# cyt4bf register map
Vendor: Cypress Semiconductor; Series: cyt4bf; File version: 1.0
CPU: CM7 r0p1, little endian, MPU, FPU, VTOR, 3 interrupt priority bits
Registers are 32-bit, read-write, reset 0x0 unless marked. A register's access mark holds for its fields unless they carry their own. Offsets are from the block's base; [hi:lo] are bit positions; 'fields as' and 'values as' point back to an identical list; <NAME> marks a mode.

## FLEXRAY0 (part 1 of 3) — FlexRay Bus Interface
Base 0x40560000
0x00 CTL — Control Register
  [31] ENABLED — This bit enables the operation of this IP. '0' : Disable. Registers FLEXRAY.CTL and FLEXRAY.DMA_CTL can be accessed normally. Access to all other registers within FLEXRAY results in a bus error response. '1' : Enable
    0=DISABLE (N/A); 1=ENABLE (N/A)
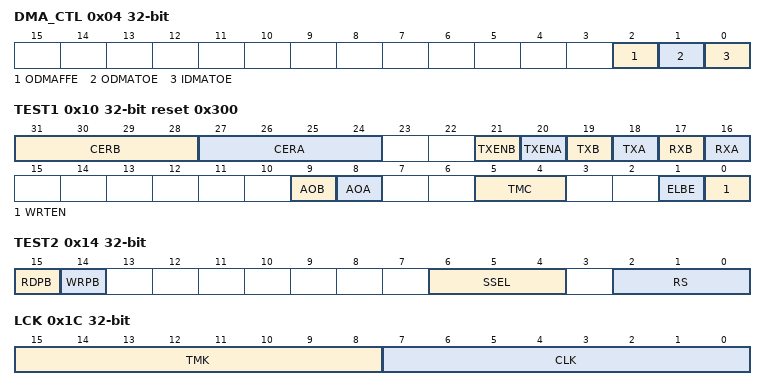
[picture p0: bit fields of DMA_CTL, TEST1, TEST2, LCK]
0x04 DMA_CTL — DMA Control Register
  [all] fields
    0=DISABLE (N/A); 1=ENABLE (N/A)
  [2] ODMAFFE — OBF DMA FIFO enable '0' : Disable: tr_obf_out is postponed until OBF is not busy. '1' : Enable: tr_obf_out is postponed until OBF is not busy AND the receive FIFO is not empty.
  [1] ODMATOE — OBF DMA trigger output enable '0' : Disable: tr_obf_out = '0'. '1' : Enable: tr_obf_out is asserted after detection of tr_obf_in according to the setting of ODMAFFE.
  [0] IDMATOE — IBF DMA trigger output enable '0' : Disable: tr_ibf_out = '0'. '1' : Enable: tr_ibf_out is asserted after the detection of tr_ibf_in, postponed until IBF is not busy.
0x10 TEST1 reset 0x300 — Test Register 1
  [31:28] CERB ro
    0=NO_CODING_ERR (N/A); 1=HEADER_CRC_ERR (N/A); 2=FRAME_CRC_ERR (N/A); 3=FRAME_START_SEQ_FSS_LONG (N/A); 4=FIRST_BIT_OF_BSS_LOW (N/A); 5=SECOND_BIT_OF_BSS_HIGH (N/A); 6=FIRST_BIT_OF_FES_HIGH (N/A); 7=SECOND_BIT_OF_FES_LOW (N/A); 8=CAS_MTS_SYMBOL_SHORT (N/A); 9=CAS_MTS_SYMBOL_LONG (N/A)
  [27:24] CERA ro
    values as CERB
  [21] TXENB — Control of Channel B Transmit Enable Pin This is used to test the interface to the physical layer (connectivity test) by driving the pin. 0 = eray_txen2_n pin drives a '0' 1 = eray_txen2_n pin drives a '1'
    0=ERAY_TXEN2_N_0 (N/A); 1=ERAY_TXEN2_N_1 (N/A)
  [20] TXENA — Control of Channel A Transmit Enable Pin This is used to test the interface to the physical layer (connectivity test) by driving the pin. 0 = eray_txen1_n pin drives a '0' 1 = eray_txen1_n pin drives a '1'
    0=ERAY_TXEN1_N_0 (N/A); 1=ERAY_TXEN1_N_1 (N/A)
  [19] TXB — Control of Channel B Transmit Pin This is used to test the interface to the physical layer (connectivity test) by driving the pin. 0 = eray_txd2 pin drives a '0' 1 = eray_txd2 pin drives a '1'
    0=ERAY_TXD2_0 (N/A); 1=ERAY_TXD2_1 (N/A)
  [18] TXA — Control of Channel A Transmit Pin This is used to test the interface to the physical layer (connectivity test) by driving the pin. 0 = eray_txd1 pin drives a '0' 1 = eray_txd1 pin drives a '1'
    0=ERAY_TXD1_0 (N/A); 1=ERAY_TXD1_1 (N/A)
  [17] RXB ro — Monitor Channel B Receive Pin This is used to test the interface to the physical layer (connectivity test) by reading the pin. 0 = eray_rxd2 = '0' 1 = eray_rxd2 = '1'
    0=ERAY_RXD2_0 (N/A); 1=ERAY_RXD2_1 (N/A)
  [16] RXA ro — Monitor Channel A Receive Pin This is used to test the interface to the physical layer (connectivity test) by reading the pin. 0 = eray_rxd1 = '0' 1 = eray_rxd1 = '1'
    0=ERAY_RXD1_0 (N/A); 1=ERAY_RXD1_1 (N/A)
  [9] AOB ro — Activity on B AOB is set when there is activity on channel B. It is reset when 11 consecutive '1' bits are detected or if the POC state is DEFAULT_CONFIG or CONFIG. During STARTUP, NORMAL_ACTIVE, or NORMAL_PASSIVE the function of AOB is the inverse of zChannel- Idle as specified in the FlexRay protocol spec v2.1, chapter 3, BITSTRB process. AOB should be ignored in all other POC states. 1 = Activity detected, channel B not idle 0 = No activity detected, channel B idle
    0=NOACT_DETECT_CH_B_IDLE (N/A); 1=ACT_DETECT_CH_B_NOT_IDLE (N/A)
  [8] AOA ro — Activity on A AOA is set when there is activity on channel A. It is reset when 11 consecutive '1' bits are detected or if the POC state is DEFAULT_CONFIG or CONFIG. During STARTUP, NORMAL_ACTIVE, or NORMAL_PASSIVE the function of AOA is the inverse of zChannelIdle as specified in the FlexRay protocol spec v2.1, chapter 3, BITSTRB process. AOA should be ignored in all other POC states. 1 = Activity detected, channel A not idle 0 = No activity detected, channel A idle
    0=NOACT_DETECT_CH_A_IDLE (N/A); 1=ACT_DETECT_CH_A_NOT_IDLE (N/A)
  [5:4] TMC — Test Multiplexer Control 00, 11= Normal signal path (default) 01 = RAM Test Mode - Internal busses are multiplexed to make all RAM blocks of the ERay module directly accessible by the Host. This mode is intended to enable testing of the embedded RAM blocks during production testing. 10 = I/O Test Mode - Output pins eray_txd1, eray_txd2, eray_txen1_n, eray_txen2_n, are driven to the values defined by bits TXA, TXB, TXENA, TXENB. The values applied to the input pins eray_rxd1, eray_rxd2 can be read from register bits RXA, RXB.
    0=NORMAL_SIGNAL_PATH (N/A); 3=NORMAL_SIGNAL_PATH_MIRROR (N/A); 1=RAM_TEST_MODE (N/A); 2=IO_TEST_MODE (N/A)
  [1] ELBE — External Loop Back Enable There are two possibilities to perform a Loop Back test. External Loop Back via physical layer or internal Loop Back for in-system self-test (default). In case of an internal Loop Back pins eray_txen1,2_n are in their inactive state, pins eray_txd1,2 are set to HIGH, pins eray_rxd1,2 are not evaluated. Bit ELBE is evaluated only when POC is in Loop Back Mode and test multiplexer control is in non-multiplexing mode TMC[1:0] = '00'. 1 = External Loop Back 0 = Internal Loop Back (default)
    0=INTERNAL_LOOP_BACK (N/A); 1=EXTERNAL_LOOP_BACK (N/A)
  [0] WRTEN — Write Test Register Enable Enables write access to the test registers. To set the bit from '0' to '1' the test mode key has to be written as defined in [01]Section 4.3.3 Lock Register (LCK). The unlock sequence is not required when WRTEN is kept at '1' while other bits of the register are changed. The bit can be reset to '0' at any time. 1 = Write access to test registers enabled 0 = Write access to test registers disabled
    0=TEST_REG_WR_DISABLED (N/A); 1=TEST_REG_WR_ENABLED (N/A)
0x14 TEST2 — Test Register 2
  [15] RDPB ro — Read Parity Bit Value of parity bit read from bit 32 of the addressed RAM word.
  [14] WRPB — Write Parity Bit Value of parity bit to be written to bit 32 of the addressed RAM word.
  [6:4] SSEL — Segment Select To enable access to the complete Message RAM (8192 byte addresses) the Message RAM is segmented. 000 = access to RAM bytes 0000h to 03FFh enabled 001 = access to RAM bytes 0400h to 07FFh enabled 010 = access to RAM bytes 0800h to 0BFFh enabled 011 = access to RAM bytes 0C00h to 0FFFh enabled 100 = access to RAM bytes 1000h to 13FFh enabled 101 = access to RAM bytes 1400h to 17FFh enabled 110 = access to RAM bytes 1800h to 1BFFh enabled 111 = access to RAM bytes 1C00h to 1FFFh enabled
    0=ADDR_0000_TO_03FF_ENABLED (N/A); 1=ADDR_0400_TO_07FF_ENABLED (N/A); 2=ADDR_0800_TO_0BFF_ENABLED (N/A); 3=ADDR_0C00_TO_0FFF_ENABLED (N/A); 4=ADDR_1000_TO_13FF_ENABLED (N/A); 5=ADDR_1400_TO_17FF_ENABLED (N/A); 6=ADDR_1800_TO_1BFF_ENABLED (N/A); 7=ADDR_1C00_TO_1FFF_ENABLED (N/A)
  [2:0] RS — RAM Select In RAM Test mode the RAM blocks selected by RS[2:0] are mapped to module address 0x400 to 7FF (1024 byte addresses). 000 = Input Buffer RAM 1 (IBF1) 001 = Input Buffer RAM 2 (IBF2) 010 = Output Buffer RAM 1 (OBF1) 011 = Output Buffer RAM 2 (OBF2) 100 = Transient Buffer RAM A (TBF1) 101 = Transient Buffer RAM B (TBF2) 110 = Message RAM (MBF) 111 = unused
    0=IBF1 (N/A); 1=IBF2 (N/A); 2=OBF1 (N/A); 3=OBF2 (N/A); 4=TBF1 (N/A); 5=TBF2 (N/A); 6=MBF (N/A)
0x1C LCK wo — Lock Register
  [15:8] TMK — Test Mode Key To write bit TEST1.WRTEN, the write operation has to be directly preceded by two consecutive write accesses to the Test Mode Key (unlock sequence). If the write sequence below is interrupted by other write accesses between the second write to the Test Mode Key and the write access to the TEST1 register, TEST1.WRTEN is not set to '1' and the sequence has to be repeated. First write: LCK.TMK[7:0] = '0111 0101' (0x75) Second write: LCK.TMK[7:0] = '1000 1010' (0x8A) Third write: TEST1.WRTEN = '1'
  [7:0] CLK — Configuration Lock Key To leave CONFIG state by writing SUCC1.CMD[3:0] (commands READY, MONITOR_MODE, ATM, LOOP_BACK), the write operation has to be directly preceded by two write accesses to the Configuration Lock Key (unlock sequence). If the write sequence below is interrupted by other write accesses between the second write to the Configuration Lock Key and the write access to the SUCC1 register, the CC remains in CONFIG state and the sequence has to be repeated. First write: LCK.CLK[7:0] = '1100 1110' (0xCE) Second write: LCK.CLK[7:0] = '0011 0001' (0x31) Third write: SUCC1.CMD[3:0]
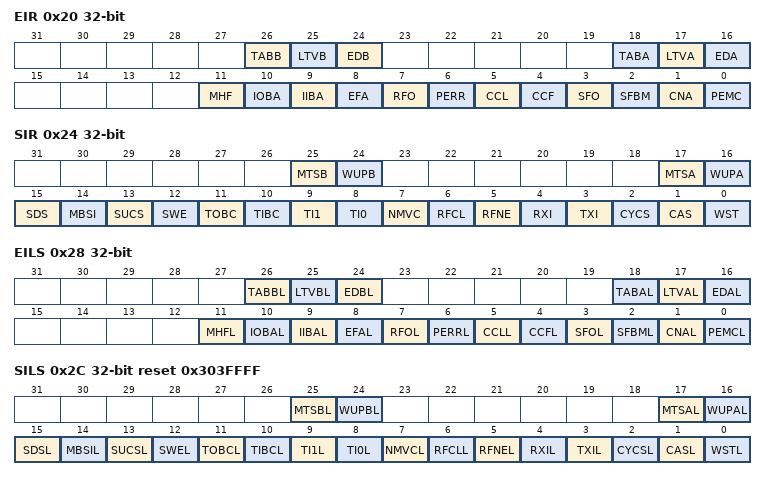
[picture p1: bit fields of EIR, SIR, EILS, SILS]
0x20 EIR — Error Interrupt Register
  [26] TABB — Transmission Across Boundary Channel B The flag signals to the Host that a transmission across a slot boundary occurred for channel B. 1 = Transmission across slot boundary detected on channel B 0 = No transmission across slot boundary detected on channel B
    0=NO_CH_B_TX_ACROSS_SLOT_BOUND_DETECTED (N/A); 1=CH_B_TX_ACROSS_SLOT_BOUND_DETECTED (N/A)
  [25] LTVB — Latest Transmit Violation Channel B The flag signals a latest transmit violation on channel B to the Host. 1 = Latest transmit violation detected on channel B 0 = No latest transmit violation detected on channel B
    0=NO_CH_B_LATEST_TX_VIOLATION_DETECTED (N/A); 1=CH_B_LATEST_TX_VIOLATION_DETECTED (N/A)
  [24] EDB — Error Detected on Channel B This bit is set whenever one of the flags ACS.SEDB, ACS.CEDB, ACS.CIB, ACS.SBVB changes from '0' to '1'. 1 = Error detected on channel B 0 = No error detected on channel B
    0=NO_CH_B_ERR_DETECTED (N/A); 1=CH_B_ERR_DETECTED (N/A)
  [18] TABA — Transmission Across Boundary Channel A The flag signals to the Host that a transmission across a slot boundary occurred for channel A. 1 = Transmission across slot boundary detected on channel A 0 = No transmission across slot boundary detected on channel A
    0=NO_CH_A_TX_ACROSS_SLOT_BOUND_DETECTED (N/A); 1=CH_A_TX_ACROSS_SLOT_BOUND_DETECTED (N/A)
  [17] LTVA — Latest Transmit Violation Channel A The flag signals a latest transmit violation on channel A to the Host. 1 = Latest transmit violation detected on channel A 0 = No latest transmit violation detected on channel A
    0=NO_CH_A_LATEST_TX_VIOLATION_DETECTED (N/A); 1=CH_A_LATEST_TX_VIOLATION_DETECTED (N/A)
  [16] EDA — Error Detected on Channel A This bit is set whenever one of the flags ACS.SEDA, ACS.CEDA, ACS.CIA, ACS.SBVA changes from '0' to '1'. 1 = Error detected on channel A 0 = No error detected on channel A
    0=NO_CH_A_ERR_DETECTED (N/A); 1=CH_A_ERR_DETECTED (N/A)
  [11] MHF — Message Handler Constraints Flag The flag signals a Message Handler constraints violation condition. It is set whenever one of the flags MHDF.SNUA, MHDF.SNUB, MHDF.FNFA, MHDF.FNFB, MHDF.TBFA, MHDF.TBFB, MHDF.WAHP changes from '0' to '1'. 1 = Message Handler failure detected 0 = No Message Handler failure detected
    0=NO_MSG_HANDLER_FAIL_DETECT (N/A); 1=MSG_HANDLER_FAIL_DETECT (N/A)
  [10] IOBA — Illegal Output buffer Access This flag is set by the CC when the Host requests the transfer of a message buffer from the Message RAM to the Output Buffer while OBCR.OBSYS is set to '1'. 1 = Illegal Host access to Output Buffer occurred 0 = No illegal Host access to Output Buffer occurred
    0=NO_ILLEGAL_OBF_ACCESS (N/A); 1=ILLEGAL_OBF_ACCESS (N/A)
  [9] IIBA — Illegal Input Buffer Access This flag is set by the CC when the Host wants to modify a message buffer via Input Buffer and one of the following conditions applies: 1) The CC is not in CONFIG or DEFAULT_CONFIG state and the Host writes to the Input Buffer Command Request register to modify the Header section of message buffer 0, 1 if configured for transmission in key slot Header section of static message buffers with buffer number < MRC.FDB[7:0] while MRC.SEC[1:0] = '01' Header section of any static or dynamic message buffer while MRC.SEC[1:0] = '1x' Header and / or data section of any message buffer belonging to the receive FIFO 2) The Host writes to any register of the Input Buffer while IBCR.IBSYH is set to '1'. 1 = Illegal Host access to Input Buffer occurred 0 = No illegal Host access to Input Buffer occurred
    0=NO_ILLEGAL_IBF_ACCESS (N/A); 1=ILLEGAL_IBF_ACCESS (N/A)
  [8] EFA — Empty FIFO Access This flag is set by the CC when the Host requests the transfer of a message from the receive FIFO via Output Buffer while the receive FIFO is empty. 1 = Host access to empty FIFO occurred 0 = No Host access to empty FIFO occurred
    0=NO_EMPTY_FIFO_ACCESS (N/A); 1=EMPTY_FIFO_ACCESS (N/A)
  [7] RFO — Receive FIFO Overrun The flag is set by the CC when a receive FIFO overrun is detected. When a receive FIFO overrun occurs, the oldest message is overwritten with the actual received message. The actual state of the FIFO is monitored in register FSR. 1 = A receive FIFO overrun has been detected 0 = No receive FIFO overrun detected
    0=NO_RECEIVE_FIFO_OVERRUN (N/A); 1=RECEIVE_FIFO_OVERRUN (N/A)
  [6] PERR — Parity Error The flag signals a parity error to the Host. It is set whenever one of the flags MHDS.PIBF, MHDS.POBF, MHDS.PMR, MHDS.PTBF1, MHDS.PTBF2 changes from '0' to '1'. 1 = Parity error detected 0 = No parity error detected
    0=NO_PARITY_ERR (N/A); 1=PARITY_ERR (N/A)
  [5] CCL — CHI Command Locked The flag signals that the write access to the CHI command vector SUCC1.CMD[3:0] was not successful because the execution of the previous CHI command has not yet completed. In this case bit CNA is also set to '1'. 1 = CHI command not accepted 0 = CHI command accepted
    0=CHI_CMD_ACCEPTED (N/A); 1=CHI_CMD_NOT_ACCEPTED (N/A)
  [4] CCF — Clock Correction Failure This flag is set at the end of the cycle whenever one of the following errors occurred: Missing offset and / or rate correction Clock correction limit reached The clock correction status is monitored in registers CCEV and SFS. A failure may occur during startup, therefore bit CCF should be cleared by the Host after the CC entered NORMAL_ACTIVE state. 1 = Clock correction failed 0 = No clock correction error
    0=NO_CLK_CORRECTION_ERR (N/A); 1=CLK_CORRECTION_ERR (N/A)
  [3] SFO — Sync Frame Overflow Set when either the number of sync frames received during the last communication cycle or the total number of different sync frame IDs received during the last double cycle exceeds the maximum number of sync frames as defined by GTUC2.SNM[3:0]. 1 = More sync frames received than configured by GTUC2.SNM[3:0] 0 = Number of received sync frames <= GTUC2.SNM[3:0]
    0=NO_SYNC_FRAME_OVERFLOW (N/A); 1=SYNC_FRAME_OVERFLOW (N/A)
  [2] SFBM — Sync Frames Below Minimum This flag signals that the number of sync frames received during the last communication cycle was below the limit required by the FlexRay protocol. May be set during startup and therefore should be cleared by the Host after the CC entered NORMAL_ACTIVE state. 1 = Less than the required minimum of sync frames received 0 = Sync node: 1 or more sync frames received, non-sync node: 2 or more sync frames received
    0=SYNC_FRAMES_NOT_BELOW_MIN (N/A); 1=SYNC_FRAMES_BELOW_MIN (N/A)
  [1] CNA — Command Not Accepted The flag signals that the write access to the CHI command vector SUCC1.CMD[3:0] was not successful because the requested command was not valid in the actual POC state, or because the CHI command was locked (CCL = '1'). 1 = CHI command not accepted 0 = CHI command accepted
    0=CHI_CMD_ACCEPTED (N/A); 1=CHI_CMD_NOT_ACCEPTED (N/A)
  [0] PEMC — POC Error Mode Changed This flag is set whenever the error mode signalled by CCEV.ERRM[1:0] has changed. 1 = Error mode has changed 0 = Error mode has not changed
    0=POC_ERR_MODE_UNCHANGED (N/A); 1=POC_ERR_MODE_CHANGED (N/A)
0x24 SIR — Status Interrupt Register
  [25] MTSB — MTS Received on Channel B (vSS!ValidMTSB) Media Access Test symbol received on channel B during the preceding symbol window. Updated by the CC for each channel at the end of the symbol window. 1 = MTS symbol received on channel B 0 = No MTS symbol received on channel B
    0=NO_MTS_SYMBOL_RXD_ON_CH_B (N/A); 1=MTS_SYMBOL_RXD_ON_CH_B (N/A)
  [24] WUPB — Wakeup Pattern Channel B This flag is set by the CC when a wakeup pattern was received on channel B. Only set when the CC is in WAKEUP, READY, or STARTUP state, or when in Monitor mode. 1 = Wakeup pattern received on channel B 0 = No wakeup pattern received on channel B
    0=NO_WAKEUP_PATTERN_RXD_ON_CH_B (N/A); 1=WAKEUP_PATTERN_RXD_ON_CH_B (N/A)
  [17] MTSA — MTS Received on Channel A (vSS!ValidMTSA) Media Access Test symbol received on channel A during the preceding symbol window. Updated by the CC for each channel at the end of the symbol window. 1 = MTS symbol received on channel A 0 = No MTS symbol received on channel A
    0=NO_MTS_SYMBOL_RXD_ON_CH_A (N/A); 1=MTS_SYMBOL_RXD_ON_CH_A (N/A)
  [16] WUPA — Wakeup Pattern Channel A This flag is set by the CC when a wakeup pattern was received on channel A. Only set when the CC is in WAKEUP, READY, or STARTUP state, or when in Monitor mode. 1 = Wakeup pattern received on channel A 0 = No wakeup pattern received on channel A
    0=NO_WAKEUP_PATTERN_RXD_ON_CH_A (N/A); 1=WAKEUP_PATTERN_RXD_ON_CH_A (N/A)
  [15] SDS — Start of Dynamic Segment This flag is set by the CC when the dynamic segment starts. 1 = Dynamic segment started 0 = Dynamic segment not yet started
    0=DYNAMIC_SEGMENT_NOT_STARTED (N/A); 1=DYNAMIC_SEGMENT_STARTED (N/A)
  [14] MBSI — Message Buffer Status Interrupt This flag is set by the CC when the message buffer status MBS has changed and if bit MBI of that message buffer is set (see Table 17). 1 = Message buffer status of at least one message buffer with MBI = '1' has changed 0 = No message buffer status change of message buffer with MBI = '1'
    0=NO_MSG_BUFF_STATUS_CHANGED (N/A); 1=MSG_BUFF_STATUS_CHANGED (N/A)
  [13] SUCS — Startup Completed Successfully This flag is set whenever a startup completed successfully and the CC entered NORMAL_ACTIVE state. 1 = Startup completed successfully 0 = No startup completed successfully
    0=NO_STARTUP_COMPLETED (N/A); 1=STARTUP_COMPLETED (N/A)
  [12] SWE — Stop Watch Event This flag is set after a stop watch activation when the actual cycle counter and macrotick value are stored in the Stop Watch register (see [01]Section 4.4.10 Stop Watch Register 1 (STPW1)). 1 = Stop Watch Event occurred 0 = No Stop Watch Event
    0=NO_STOP_WATCH_EVENT (N/A); 1=STOP_WATCH_EVENT_OCCURRED (N/A)
  [11] TOBC — Transfer Output Buffer Completed This flag is set whenever a transfer from the Message RAM to the Output Buffer has completed and OBCR.OBSYS has been reset by the Message Handler. 1 = Transfer between Message RAM and Output Buffer completed 0 = No transfer completed
    0=NO_TRANSFER_COMPLETED (N/A); 1=MSGRAM_TO_OBF_TRANSFER_COMPLETED (N/A)
  [10] TIBC — Transfer Input Buffer Completed This flag is set whenever a transfer from Input Buffer to the Message RAM has completed and IBCR.IBSYS has been reset by the Message Handler. 1 = Transfer between Input Buffer and Message RAM completed 0 = No transfer completed
    0=NO_TRANSFER_COMPLETED (N/A); 1=IBF_TO_MSGRAM_TRANSFER_COMPLETED (N/A)
  [9] TI1 — Timer Interrupt 1 This flag is set whenever timer 1 matches the conditions configured in register T1C. A Timer Interrupt 1 is also signalled on pin eray_tint1. 1 = Timer Interrupt 1 occurred 0 = No Timer Interrupt 1
    0=NO_TIMER_INTERRUPT_1 (N/A); 1=TIMER_INTERRUPT_1_OCCURED (N/A)
  [8] TI0 — Timer Interrupt 0 This flag is set whenever timer 0 matches the conditions configured in register T0C. A Timer Interrupt 0 is also signalled on pin eray_tint0. 1 = Timer Interrupt 0 occurred 0 = No Timer Interrupt 0
    0=NO_TIMER_INTERRUPT_0 (N/A); 1=TIMER_INTERRUPT_0_OCCURED (N/A)
  [7] NMVC — Network Management Vector Changed This interrupt flag signals a change in the Network Management Vector visible to the Host. 1 = Network management vector changed 0 = No change in the network management vector
    0=NTWK_MGMT_VECTOR_UNCHANGED (N/A); 1=NTWK_MGMT_VECTOR_CHANGED (N/A)
  [6] RFCL — Receive FIFO Critical Level This flag is set when the receive FIFO fill level FSR.RFFL[7:0] is equal or greater than the critical level as configured by FCL.CL[7:0]. 1 = Receive FIFO critical level reached 0 = Receive FIFO below critical level
    0=RX_FIFO_BELOW_CRITICAL_LEVEL (N/A); 1=RX_FIFO_NOT_BELOW_CRITICAL_LEVEL (N/A)
  [5] RFNE — Receive FIFO Not Empty This flag is set by the CC when a received valid frame was stored into the empty receive FIFO. The actual state of the receive FIFO is monitored in register FSR. 1 = Receive FIFO is not empty 0 = Receive FIFO is empty
    0=RX_FIFO_EMPTY (N/A); 1=RX_FIFO_NOT_EMPTY (N/A)
  [4] RXI — Receive Interrupt This flag is set by the CC whenever the set condition of a message buffers ND flag is fulfilled see 4.8.6 New Data 1/2/3/4 (NDAT1/2/3/4)), and if bit MBI of that message buffer is set to '1' see Table 17). 1 = At least one ND flag of a receive buffer with MBI = '1' has been set to '1' 0 = No ND flag of a receive buffer with MBI = '1' has been set to '1'
    0=NO_ND_FLAG_OF_RX_MBI_BUFF_SET (N/A); 1=ND_FLAG_OF_RX_MBI_BUFF_SET (N/A)
  [3] TXI — Transmit Interrupt This flag is set by the CC at the end of frame transmission if bit MBI in the respective message buffer is set to '1' (see Table 17). 1 = At least one frame was transmitted from a transmit buffer with MBI = '1' 0 = No frame transmitted from a transmit buffer with MBI = '1'
    0=NO_FRAME_TXED_FROM_TX_MBI_BUFF (N/A); 1=FRAME_TXED_FROM_TX_MBI_BUFF (N/A)
  [2] CYCS — Cycle Start Interrupt This flag is set by the CC when a communication cycle starts. 1 = Communication cycle started 0 = No communication cycle started
    0=NO_COMM_CYCLE_STARTED (N/A); 1=COMM_CYCLE_STARTED (N/A)
  [1] CAS — Collision Avoidance Symbol This flag is set by the CC during STARTUP state when a CAS or a potential CAS was received. 1 = Bit pattern matching the CAS symbol received 0 = No bit pattern matching the CAS symbol received
    0=NO_CAS_BIT_PATTERN_MATCH (N/A); 1=CAS_BIT_PATTERN_MATCH (N/A)
  [0] WST — Wakeup Status This flag is set when CCSV.WSV[2:0] changes to a value other than UNDEFINED. 1 = Wakeup status changed 0 = Wakeup status unchanged
    0=WAKEUP_STATUS_UNCHANGED (N/A); 1=WAKEUP_STATUS_CHANGED (N/A)
0x28 EILS — Error Interrupt Line Select
  [26] TABBL — Transmission Across Boundary Channel B Interrupt Line
  [25] LTVBL — Latest Transmit Violation Channel B Interrupt Line
  [24] EDBL — Error Detected on Channel B Interrupt Line
  [18] TABAL — Transmission Across Boundary Channel A Interrupt Line
  [17] LTVAL — Latest Transmit Violation Channel A Interrupt Line
  [16] EDAL — Error Detected on Channel A Interrupt Line
  [11] MHFL — Message Handler Constraints Flag Interrupt Line
  [10] IOBAL — Illegal Output Buffer Access Interrupt Line
  [9] IIBAL — Illegal Input Buffer Access Interrupt Line
  [8] EFAL — Empty FIFO Access Interrupt Line
  [7] RFOL — Receive FIFO Overrun Interrupt Line
  [6] PERRL — Parity Error Interrupt Line
  [5] CCLL — CHI Command Locked Interrupt Line
  [4] CCFL — Clock Correction Failure Interrupt Line
  [3] SFOL — Sync Frame Overflow Interrupt Line
  [2] SFBML — Sync Frames Below Minimum Interrupt Line
  [1] CNAL — Command Not Accepted Interrupt Line
  [0] PEMCL — POC Error Mode Changed Interrupt Line
0x2C SILS reset 0x303FFFF — Status Interrupt Line Select
  [25] MTSBL — Media Access Test Symbol Channel B Interrupt Line
  [24] WUPBL — Wakeup Pattern Channel B Interrupt Line
  [17] MTSAL — Media Access Test Symbol Channel A Interrupt Line
  [16] WUPAL — Wakeup Pattern Channel A Interrupt Line
  [15] SDSL — Start of Dynamic Segment Interrupt Line
  [14] MBSIL — Message Buffer Status Interrupt Line
  [13] SUCSL — Startup Completed Successfully Interrupt Line
  [12] SWEL — Stop Watch Event Interrupt Line
  [11] TOBCL — Transfer Output Buffer Completed Interrupt Line
  [10] TIBCL — Transfer Input Buffer Completed Interrupt Line
  [9] TI1L — Timer Interrupt 1 Line
  [8] TI0L — Timer Interrupt 0 Line
  [7] NMVCL — Network Management Vector Changed Interrupt Line
  [6] RFCLL — Receive FIFO Critical Level Interrupt Line
  [5] RFNEL — Receive FIFO Not Empty Interrupt Line
  [4] RXIL — Receive Interrupt Line
  [3] TXIL — Transmit Interrupt Line
  [2] CYCSL — Cycle Start Interrupt Line
  [1] CASL — Collision Avoidance Symbol Interrupt Line
  [0] WSTL — Wakeup Status Interrupt Line
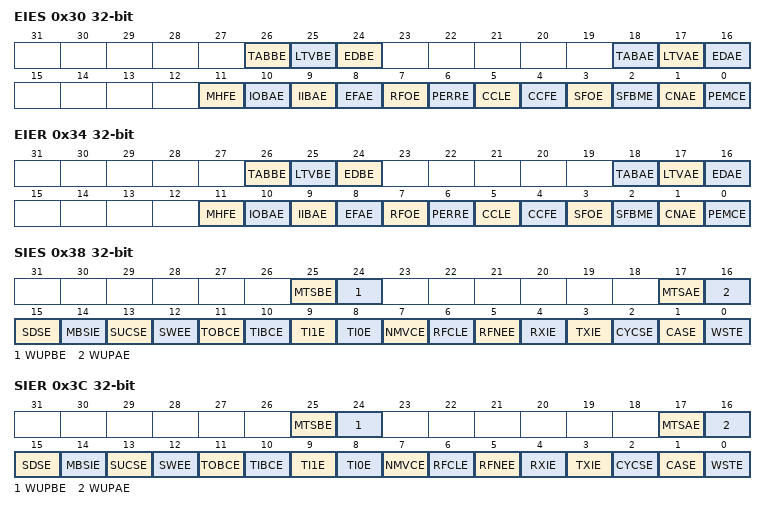
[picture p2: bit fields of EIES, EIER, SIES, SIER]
0x30 EIES — Error Interrupt Enable Set
  [26] TABBE — Transmission Across Boundary Channel B Interrupt Enable
  [25] LTVBE — Latest Transmit Violation Channel B Interrupt Enable
  [24] EDBE — Error Detected on Channel B Interrupt Enable
  [18] TABAE — Transmission Across Boundary Channel A Interrupt Enable
  [17] LTVAE — Latest Transmit Violation Channel A Interrupt Enable
  [16] EDAE — Error Detected on Channel A Interrupt Enable
  [11] MHFE — Message Handler Constraints Flag Interrupt Enable
  [10] IOBAE — Illegal Output Buffer Access Interrupt Enable
  [9] IIBAE — Illegal Input Buffer Access Interrupt Enable
  [8] EFAE — Empty FIFO Access Interrupt Enable
  [7] RFOE — Receive FIFO Overrun Interrupt Enable
  [6] PERRE — Parity Error Interrupt Enable
  [5] CCLE — CHI Command Locked Interrupt Enable
  [4] CCFE — Clock Correction Failure Interrupt Enable
  [3] SFOE — Sync Frame Overflow Interrupt Enable
  [2] SFBME — Sync Frames Below Minimum Interrupt Enable
  [1] CNAE — Command Not Accepted Interrupt Enable
  [0] PEMCE — POC Error Mode Changed Interrupt Enable
0x34 EIER — Error Interrupt Enable Reset
  fields as EIES
0x38 SIES — Status Interrupt Enable Set
  [25] MTSBE — MTS Received on Channel B Interrupt Enable
  [24] WUPBE — Wakeup Pattern Channel B Interrupt Enable
  [17] MTSAE — MTS Received on Channel A Interrupt Enable
  [16] WUPAE — Wakeup Pattern Channel A Interrupt Enable
  [15] SDSE — Start of Dynamic Segment Interrupt Enable
  [14] MBSIE — Message Buffer Status Interrupt Enable
  [13] SUCSE — Startup Completed Successfully Interrupt Enable
  [12] SWEE — Stop Watch Event Interrupt Enable
  [11] TOBCE — Transfer Output Buffer Completed Interrupt Enable
  [10] TIBCE — Transfer Input Buffer Completed Interrupt Enable
  [9] TI1E — Timer Interrupt 1 Enable
  [8] TI0E — Timer Interrupt 0 Enable
  [7] NMVCE — Network Management Vector Changed Interrupt Enable
  [6] RFCLE — Receive FIFO Critical Level Interrupt Enable
  [5] RFNEE — Receive FIFO Not Empty Interrupt Enable
  [4] RXIE — Receive Interrupt Enable
  [3] TXIE — Transmit Interrupt Enable
  [2] CYCSE — Cycle Start Interrupt Enable
  [1] CASE — Collision Avoidance Symbol Interrupt Enable
  [0] WSTE — Wakeup Status Interrupt Enable
0x3C SIER — Status Interrupt Enable Reset
  fields as SIES
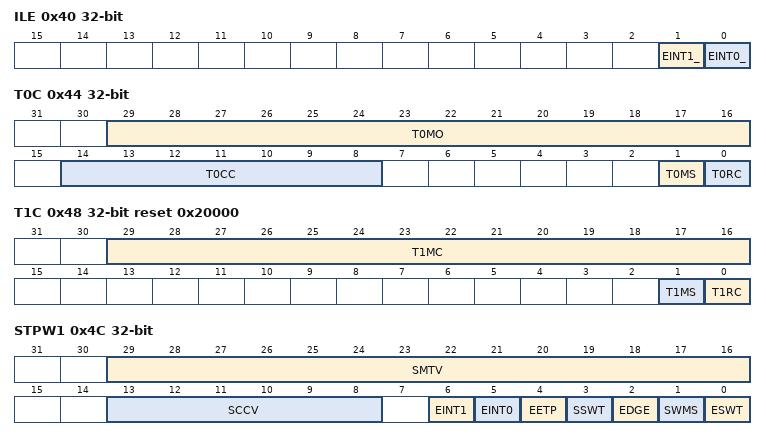
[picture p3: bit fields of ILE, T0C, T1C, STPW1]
0x40 ILE — Interrupt Line Enable
  [1] EINT1_ — Enable Interrupt Line 1 1 = Interrupt line eray_int1 enabled 0 = Interrupt line eray_int1 disabled
    0=ERAY_INT1_DISABLED (N/A); 1=ERAY_INT1_ENABLED (N/A)
  [0] EINT0_ — Enable Interrupt Line 0 1 = Interrupt line eray_int0 enabled 0 = Interrupt line eray_int0 disabled
    0=ERAY_INT0_DISABLED (N/A); 1=ERAY_INT0_ENABLED (N/A)
0x44 T0C — Timer 0 Configuration
  [29:16] T0MO — Timer 0 Macrotick Offset Configures the macrotick offset from the beginning of the cycle where the interrupt is to occur. The Timer 0 Interrupt occurs at this offset for each cycle of the cycle set.
  [14:8] T0CC — Timer 0 Cycle Code The 7-bit timer 0 cycle code determines the cycle set used for generation of the timer 0 interrupt. For details about the configuration of the cycle code see [01]Section 5.7.2 Cycle Counter Filtering.
  [1] T0MS — Timer 0 Mode Select 1 = Continuous mode 0 = Single-shot mode
    0=TIMER_0_SINGLE_SHOT_MODE (N/A); 1=TIMER_0_CONTINUOUS_MODE (N/A)
  [0] T0RC — Timer 0 Run Control 1 = Timer 0 running 0 = Timer 0 halted
    0=TIMER_0_HALTED (N/A); 1=TIMER_0_RUNNING (N/A)
0x48 T1C reset 0x20000 — Timer 1 Configuration
  [29:16] T1MC — Timer 1 Macrotick Count When the configured macrotick count is reached the timer 1 interrupt is generated. Valid values are: 2 to 16383 MT in continuous mode 1 to 16383 MT in single-shot mode
    1=MIN (N/A); 0x3FFF=MAX (N/A)
  [1] T1MS — Timer 1 Mode Select 1 = Continuous mode 0 = Single-shot mode
    0=TIMER_1_SINGLE_SHOT_MODE (N/A); 1=TIMER_1_CONTINUOUS_MODE (N/A)
  [0] T1RC — Timer 1 Run Control 1 = Timer 1 running 0 = Timer 1 halted
    0=TIMER_1_HALTED (N/A); 1=TIMER_1_RUNNING (N/A)
0x4C STPW1 — Stop Watch Register 1
  [29:16] SMTV ro — Stop Watch Captured Macrotick Value State of the macrotick counter when the stop watch event occurred. Valid values are 0 to 15999.
    0x3E7F=MAX (N/A)
  [13:8] SCCV ro — Stop Watch Captured Cycle Counter Value State of the cycle counter when the stop watch event occurred. Valid values are 0 to 63.
  [6] EINT1 — Enable Interrupt 1 Trigger Enables stop watch trigger by interrupt 1event if ESWT = '1'. 1 = Interrupt 1 event triggers stop watch 0 = Stop watch trigger by interrupt 1 disabled
    0=STPWT_TRIGGER_BY_INT1_DISABLED (N/A); 1=STPWT_TRIGGER_BY_INT1_ENABLED (N/A)
  [5] EINT0 — Enable Interrupt 0 Trigger Enables stop watch trigger by interrupt 0 event if ESWT = '1'. 1 = Interrupt 0 event triggers stop watch 0 = Stop watch trigger by interrupt 0 disabled
    0=STPWT_TRIGGER_BY_INT0_DISABLED (N/A); 1=STPWT_TRIGGER_BY_INT0_ENABLED (N/A)
  [4] EETP — Enable External Trigger Pin Enables stop watch trigger event via pin eray_stpwt if ESWT = '1'. 1 = Edge on pin eray_stpwt triggers stop watch 0 = Stop watch trigger via pin eray_stpwt disabled
    0=ESTPWT_DISABLED (N/A); 1=ESTPWT_ENABLED (N/A)
  [3] SSWT — Software Stop Watch Trigger When the Host writes this bit to '1' the stop watch is activated. After the actual cycle counter and macrotick value are stored in the Stop Watch register this bit is reset to '0'. The bit is only writeable while ESWT = '0'. 1 = Stop watch activated by software trigger 0 = Software trigger reset
    0=STOP_WATCH_SOFTWARE_TRIGGER_RESET (N/A); 1=STOP_WATCH_SOFTWARE_TRIGGER_ACTIVATED (N/A)
  [2] EDGE — Stop Watch Trigger Edge Select 1 = Rising edge 0 = Falling edge
    0=STOP_WATCH_FALLING_EDGE (N/A); 1=STOP_WATCH_RISING_EDGE (N/A)
  [1] SWMS — Stop Watch Mode Select 1 = Continuous mode 0 = Single-shot mode
    0=STOP_WATCH_SINGLE_SHOT_MODE (N/A); 1=STOP_WATCH_CONTINUOUS_MODE (N/A)
  [0] ESWT — Enable Stop Watch Trigger If enabled an edge on input eray_stpwt or an interrupt 0,1 event (rising edge on pin eray_int0 or eray_int1) activates the stop watch. In single-shot mode this bit is reset to '0' after the actual cycle counter and macrotick value are stored in the Stop Watch register. 1 = Stop watch trigger enabled 0 = Stop watch trigger disabled
    0=STOP_WATCH_TRIGGER_DISABLED (N/A); 1=STOP_WATCH_TRIGGER_ENABLED (N/A)
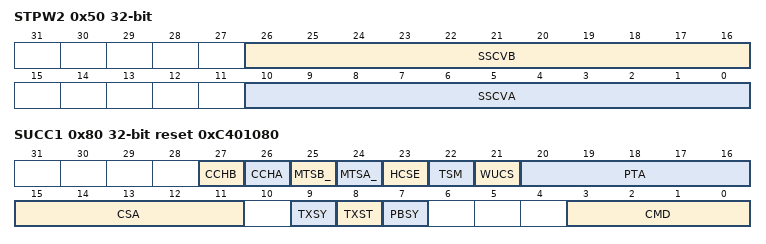
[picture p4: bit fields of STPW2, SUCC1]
0x50 STPW2 ro — Stop Watch Register 2
  [26:16] SSCVB — Stop Watch Captured Slot Counter Value Channel B State of the slot counter for channel B when the stop watch event occurred. Valid values are 0 to 2047.
  [10:0] SSCVA — Stop Watch Captured Slot Counter Value Channel A State of the slot counter for channel A when the stop watch event occurred. Valid values are 0 to 2047.
0x80 SUCC1 reset 0xC401080 — SUC Configuration Register 1
  [27] CCHB — Connected to Channel B (pChannels) Configures whether the node is connected to channel B. 1 = Node connected to channel B (default after hard reset) 0 = Not connected to channel B
    0=CH_B_NOT_CONNECTED (N/A); 1=CH_B_CONNECTED (N/A)
  [26] CCHA — Connected to Channel A (pChannels) Configures whether the node is connected to channel A. 1 = Node connected to channel A (default after hard reset) 0 = Not connected to channel A
    0=CH_A_NOT_CONNECTED (N/A); 1=CH_A_CONNECTED (N/A)
  [25] MTSB_ — Select Channel B for MTS Transmission The bit selects channel B for MTS symbol transmission. The flag is reset by default and may be modified only in DEFAULT_CONFIG or CONFIG state. 1 = Channel B selected for MTS transmission 0 = Channel B disabled for MTS transmission
    0=CH_B_DISABLED_FOR_MTS_TXMN (N/A); 1=CH_B_SELECTED_FOR_MTS_TXMN (N/A)
  [24] MTSA_ — Select Channel A for MTS Transmission The bit selects channel A for MTS symbol transmission. The flag is reset by default and may be modified only in DEFAULT_CONFIG or CONFIG state. 1 = Channel A selected for MTS transmission 0 = Channel A disabled for MTS transmission
    0=CH_A_DISABLED_FOR_MTS_TXMN (N/A); 1=CH_A_SELECTED_FOR_MTS_TXMN (N/A)
  [23] HCSE — Halt due to Clock Sync Error (pAllowHaltDueToClock) Controls the transition to HALT state due to a clock synchronization error. The bit can be modified in DEFAULT_CONFIG or CONFIG state only. 1 = CC will enter HALT state 0 = CC will enter / remain in NORMAL_PASSIVE
    0=CC_TO_ENTER_NORMAL_PASSIVE (N/A); 1=CC_TO_ENTER_HALT (N/A)
  [22] TSM — Transmission Slot Mode (pSingleSlotEnabled) Selects the initial transmission slot mode. In SINGLE slot mode the CC may only transmit in the preconfigured key slot. The key slot ID is configured in the header section of message buffer 0 respectively message buffers 0 and 1 depending on bit MRC.SPLM. In case TSM = '1', message buffer 0 respectively message buffers 0,1 can be (re)configured in DEFAULT_CONFIG or CONFIG state only. In ALL slot mode the CC may transmit in all slots. TSM is a configuration bit which can only be set / reset by the Host. The bit can be written in DEFAULT_CONFIG or CONFIG state only. The CC changes to ALL slot mode when the Host successfully applied the ALL_SLOTS command by writing CMD[3:0] = '0101' in POC states NORMAL_ACTIVE or NORMAL_PASSIVE. The actual slot mode is monitored by CCSV.SLM[1:0]. 1 = SINGLE Slot Mode (default after hard reset) 0 = ALL Slot Mode
    0=ALL_SLOT_MODE (N/A); 1=SINGLE_SLOT_MODE (N/A)
  [21] WUCS — Wakeup Channel Select (pWakeupChannel) With this bit the Host selects the channel on which the CC sends the Wakeup pattern. The CC ignores any attempt to change the status of this bit when not in DEFAULT_CONFIG or CONFIG state. 1 = Send wakeup pattern on channel B 0 = Send wakeup pattern on channel A
    0=SEND_WKUP_PATTERN_ON_CH_A (N/A); 1=SEND_WKUP_PATTERN_ON_CH_B (N/A)
  [20:16] PTA — Passive to Active (pAllowPassiveToActive) Defines the number of consecutive even / odd cycle pairs that must have valid clock correction terms before the CC is allowed to transit from NORMAL_PASSIVE to NORMAL_ACTIVE state. If set to '00000' the CC is not allowed to transit from NORMAL_PASSIVE to NORMAL_ACTIVE state. It can be modified in DEFAULT_CONFIG or CONFIG state only. Valid values are 0 to 31 even / odd cycle pairs.
  [15:11] CSA — Cold Start Attempts (gColdStartAttempts) Configures the maximum number of attempts that a cold starting node is permitted to try to start up the network without receiving any valid response from another node. It can be modified in DEFAULT_CONFIG or CONFIG state only. Must be identical in all nodes of a cluster. Valid values are 2 to 31.
    2=MIN (N/A)
  [9] TXSY — Transmit Sync Frame in Key Slot (pKeySlotUsedForSync) Defines whether the key slot is used to transmit sync frames. The bit can be modified in DEFAULT_CONFIG or CONFIG state only. 1 = Key slot used to transmit sync frame, node is sync node 0 = No sync frame transmission in key slot, node is neither sync nor coldstart node
    0=NO_SYNC_FRAME_TXMN (N/A); 1=SYNC_FRAME_TXMN (N/A)
  [8] TXST — Transmit Startup Frame in Key Slot (pKeySlotUsedForStartup) Defines whether the key slot is used to transmit startup frames. The bit can be modified in DEFAULT_CONFIG or CONFIG state only. 1 = Key slot used to transmit startup frame, node is leading or following coldstarter 0 = No startup frame transmission in key slot, node is non-coldstarter
    0=NO_STARTUP_FRAME_TXMN (N/A); 1=STARTUP_FRAME_TXMN (N/A)
  [7] PBSY ro — POC Busy Signals that the POC is busy and cannot accept a command from the Host. CMD[3:0] is locked against write accesses. Set to '1' after hard reset during initialization of internal RAM blocks. 1 = POC is busy, CMD[3:0] locked 0 = POC not busy, CMD[3:0] writeable
    0=POC_NOT_BUSY (N/A); 1=POC_BUSY (N/A)
  [3:0] CMD
    0=CMD_NOT_ACCEPTED (N/A); 1=CONFIG (N/A); 2=READY (N/A); 3=WAKEUP (N/A); 4=RUN (N/A); 5=ALL_SLOTS (N/A); 6=HALT (N/A); 7=FREEZE (N/A); 8=SEND_MTS (N/A); 9=ALLOW_COLDSTART (N/A); 10=RESET_STATUS_INDICATORS (N/A); 11=MONITOR_MODE (N/A); 12=CLEAR_RAMS (N/A)

## Notices in the file
Copyright 2016-2019, Cypress Semiconductor Corporation.  All rights reserved.
You may use this file only in accordance with the license, terms, conditions,
disclaimers, and limitations in the end user license agreement accompanying
the software package with which this file was provided.
